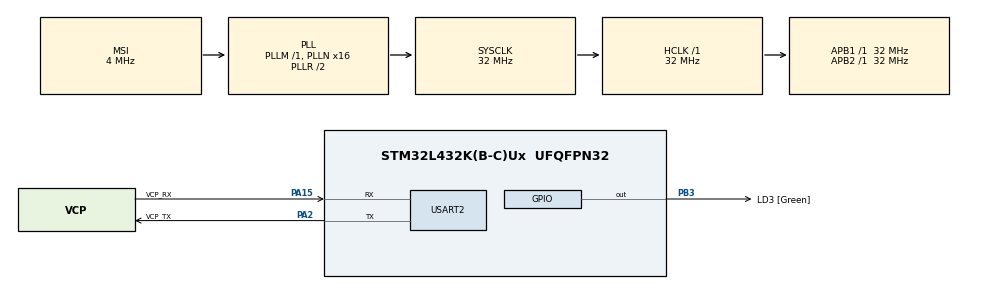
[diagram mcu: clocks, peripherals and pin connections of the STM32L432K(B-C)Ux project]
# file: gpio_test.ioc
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FREERTOS.BinarySemaphores01=myBinarySem01,Dynamic,NULL
FREERTOS.Mutexes01=myMutex01,Dynamic,NULL
FREERTOS.Tasks01=defaultTask,0,128,Task0,Default,NULL,Dynamic,NULL,NULL;myTask02,-3,128,Task1,Default,NULL,Dynamic,NULL,NULL;myTask03,-3,128,Task2,Default,NULL,Dynamic,NULL,NULL
Mcu.Family=STM32L4
Mcu.Name=STM32L432K(B-C)Ux
Mcu.Package=UFQFPN32
NVIC.PriorityGroup=NVIC_PRIORITYGROUP_4
PA0.GPIO_Label=MCO [High speed clock in]
PA0.Mode=HSE-External-Clock-Source-for-LittleOrca
PA0.Signal=RCC_CK_IN
PA13\ (JTMS-SWDIO).GPIO_Label=SWDIO
PA13\ (JTMS-SWDIO).Mode=Serial_Wire
PA13\ (JTMS-SWDIO).Signal=SYS_JTMS-SWDIO
PA14\ (JTCK-SWCLK).GPIO_Label=SWCLK
PA14\ (JTCK-SWCLK).Mode=Serial_Wire
PA14\ (JTCK-SWCLK).Signal=SYS_JTCK-SWCLK
PA15\ (JTDI).GPIO_Label=VCP_RX
PA15\ (JTDI).Mode=Asynchronous
PA15\ (JTDI).Signal=USART2_RX
PA2.GPIO_Label=VCP_TX
PA2.Mode=Asynchronous
PA2.Signal=USART2_TX
PB3\ (JTDO-TRACESWO).GPIO_Label=LD3 [Green]
PB3\ (JTDO-TRACESWO).Signal=GPIO_Output
PC14-OSC32_IN\ (PC14).Mode=LSE-External-Oscillator
PC14-OSC32_IN\ (PC14).Signal=RCC_OSC32_IN
PC15-OSC32_OUT\ (PC15).Mode=LSE-External-Oscillator
PC15-OSC32_OUT\ (PC15).Signal=RCC_OSC32_OUT
ProjectManager.HeapSize=0x200
ProjectManager.StackSize=0x400
ProjectManager.TargetToolchain=Makefile
RCC.AHBFreq_Value=32000000
RCC.APB1Freq_Value=32000000
RCC.APB1TimFreq_Value=32000000
RCC.APB2Freq_Value=32000000
RCC.APB2TimFreq_Value=32000000
RCC.CortexFreq_Value=32000000
RCC.HCLKFreq_Value=32000000
RCC.HSE_VALUE=8000000
RCC.HSI16_VALUE=16000000
RCC.HSI48_VALUE=48000000
RCC.HSI_VALUE=16000000
RCC.MSI_VALUE=4000000
RCC.PLLMUL=RCC_PLLMUL_4
RCC.PLLN=16
RCC.SYSCLKFreq_VALUE=32000000
RCC.SYSCLKSource=RCC_SYSCLKSOURCE_PLLCLK
RCC.VCOOutputFreq_Value=64000000
USART2.VirtualMode-Asynchronous=VM_ASYNC
VP_FREERTOS_VS_CMSIS_V1.Mode=CMSIS_V1
board=NUCLEO-L432KC

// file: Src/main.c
/* USER CODE BEGIN Header */
/**
  ******************************************************************************
  * @file           : main.c
  * @brief          : Main program body
  ******************************************************************************
  * @attention
  *
  * <h2><center>&copy; Copyright (c) 2019 STMicroelectronics.
  * All rights reserved.</center></h2>
  *
  * This software component is licensed by ST under Ultimate Liberty license
  * SLA0044, the "License"; You may not use this file except in compliance with
  * the License. You may obtain a copy of the License at:
  *                             www.st.com/SLA0044
  *
  ******************************************************************************
  */
/* USER CODE END Header */

#include "main.h"
#include "cmsis_os.h"
#include "usart.h"
#include "gpio.h"

void SystemClock_Config(void);
void MX_FREERTOS_Init(void);

int main(void) {

    /* MCU Configuration--------------------------------------------------------*/

    /* Reset of all peripherals, Initializes the Flash interface and the Systick. */
    HAL_Init();

    /* Configure the system clock */
    SystemClock_Config();

    /* Initialize all configured peripherals */
    MX_GPIO_Init();
    MX_USART2_UART_Init();

    /* Call init function for freertos objects (in freertos.c) */
    MX_FREERTOS_Init();

    /* Start scheduler */
    osKernelStart();

    /* We should never get here as control is now taken by the scheduler */

    /* Infinite loop */
    while (1) {

    }
}

void SystemClock_Config(void) {
    RCC_OscInitTypeDef RCC_OscInitStruct = {0};
    RCC_ClkInitTypeDef RCC_ClkInitStruct = {0};
    RCC_PeriphCLKInitTypeDef PeriphClkInit = {0};

    /** Configure LSE Drive Capability
    */
    HAL_PWR_EnableBkUpAccess();
    __HAL_RCC_LSEDRIVE_CONFIG(RCC_LSEDRIVE_LOW);
    /** Initializes the CPU, AHB and APB busses clocks
    */
    RCC_OscInitStruct.OscillatorType = RCC_OSCILLATORTYPE_LSE|RCC_OSCILLATORTYPE_MSI;
    RCC_OscInitStruct.LSEState = RCC_LSE_ON;
    RCC_OscInitStruct.MSIState = RCC_MSI_ON;
    RCC_OscInitStruct.MSICalibrationValue = 0;
    RCC_OscInitStruct.MSIClockRange = RCC_MSIRANGE_6;
    RCC_OscInitStruct.PLL.PLLState = RCC_PLL_ON;
    RCC_OscInitStruct.PLL.PLLSource = RCC_PLLSOURCE_MSI;
    RCC_OscInitStruct.PLL.PLLM = 1;
    RCC_OscInitStruct.PLL.PLLN = 16;
    RCC_OscInitStruct.PLL.PLLP = RCC_PLLP_DIV7;
    RCC_OscInitStruct.PLL.PLLQ = RCC_PLLQ_DIV2;
    RCC_OscInitStruct.PLL.PLLR = RCC_PLLR_DIV2;
    if (HAL_RCC_OscConfig(&RCC_OscInitStruct) != HAL_OK) {
        Error_Handler();
    }
    /** Initializes the CPU, AHB and APB busses clocks
    */
    RCC_ClkInitStruct.ClockType = RCC_CLOCKTYPE_HCLK|RCC_CLOCKTYPE_SYSCLK
                                  |RCC_CLOCKTYPE_PCLK1|RCC_CLOCKTYPE_PCLK2;
    RCC_ClkInitStruct.SYSCLKSource = RCC_SYSCLKSOURCE_PLLCLK;
    RCC_ClkInitStruct.AHBCLKDivider = RCC_SYSCLK_DIV1;
    RCC_ClkInitStruct.APB1CLKDivider = RCC_HCLK_DIV1;
    RCC_ClkInitStruct.APB2CLKDivider = RCC_HCLK_DIV1;

    if (HAL_RCC_ClockConfig(&RCC_ClkInitStruct, FLASH_LATENCY_1) != HAL_OK) {
        Error_Handler();
    }
    PeriphClkInit.PeriphClockSelection = RCC_PERIPHCLK_USART2;
    PeriphClkInit.Usart2ClockSelection = RCC_USART2CLKSOURCE_PCLK1;
    if (HAL_RCCEx_PeriphCLKConfig(&PeriphClkInit) != HAL_OK) {
        Error_Handler();
    }
    /** Configure the main internal regulator output voltage
    */
    if (HAL_PWREx_ControlVoltageScaling(PWR_REGULATOR_VOLTAGE_SCALE1) != HAL_OK) {
        Error_Handler();
    }
    /** Enable MSI Auto calibration
    */
    HAL_RCCEx_EnableMSIPLLMode();
}

void Error_Handler(void) {
}

/************************ (C) COPYRIGHT STMicroelectronics *****END OF FILE****/

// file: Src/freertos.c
/* USER CODE BEGIN Header */
/**
  ******************************************************************************
  * File Name          : freertos.c
  * Description        : Code for freertos applications
  ******************************************************************************
  * @attention
  *
  * <h2><center>&copy; Copyright (c) 2019 STMicroelectronics.
  * All rights reserved.</center></h2>
  *
  * This software component is licensed by ST under Ultimate Liberty license
  * SLA0044, the "License"; You may not use this file except in compliance with
  * the License. You may obtain a copy of the License at:
  *                             www.st.com/SLA0044
  *
  ******************************************************************************
  */
/* USER CODE END Header */

#include "FreeRTOS.h"
#include "task.h"
#include "main.h"
#include "cmsis_os.h"

/* USER CODE BEGIN Includes */
#include "gpio.h"
#include "usart.h"
#include <stdio.h>
#include <string.h>
/* USER CODE END Includes */

osThreadId defaultTaskHandle;
osThreadId myTask02Handle;
osThreadId myTask03Handle;
osMutexId myMutex01Handle;
osSemaphoreId myBinarySem01Handle;

void Task0(void const * argument);
void Task1(void const * argument);
void Task2(void const * argument);

void MX_FREERTOS_Init(void); /* (MISRA C 2004 rule 8.1) */

void MX_FREERTOS_Init(void) {

    /* Create the mutex(es) */
    /* definition and creation of myMutex01 */
    osMutexDef(myMutex01);
    myMutex01Handle = osMutexCreate(osMutex(myMutex01));

    /* Create the semaphores(s) */
    /* definition and creation of myBinarySem01 */
    osSemaphoreDef(myBinarySem01);
    myBinarySem01Handle = osSemaphoreCreate(osSemaphore(myBinarySem01), 1);

    /* Create the thread(s) */
    /* definition and creation of defaultTask */
    osThreadDef(defaultTask, Task0, osPriorityNormal, 0, 128);
    defaultTaskHandle = osThreadCreate(osThread(defaultTask), NULL);

    /* definition and creation of myTask02 */
    osThreadDef(myTask02, Task1, osPriorityIdle, 0, 128);
    myTask02Handle = osThreadCreate(osThread(myTask02), NULL);

    /* definition and creation of myTask03 */
    osThreadDef(myTask03, Task2, osPriorityIdle, 0, 128);
    myTask03Handle = osThreadCreate(osThread(myTask03), NULL);

}

void Task0(void const * argument) {

    for(;;) {
        osDelay(1);
    }
}

void Task1(void const * argument) {
    /* USER CODE BEGIN Task1 */

    GPIO_InitTypeDef GPIO_InitStruct = {0};

    /*Configure GPIO pin Output Level */
    HAL_GPIO_WritePin(GPIOA, GPIO_PIN_4, GPIO_PIN_RESET);
    HAL_GPIO_WritePin(GPIOA, GPIO_PIN_5, GPIO_PIN_SET);

    /*Configure GPIO pin : PA_4 */
    GPIO_InitStruct.Pin = GPIO_PIN_4;
    GPIO_InitStruct.Mode = GPIO_MODE_OUTPUT_PP;
    GPIO_InitStruct.Pull = GPIO_NOPULL;
    GPIO_InitStruct.Speed = GPIO_SPEED_FREQ_LOW;
    HAL_GPIO_Init(GPIOA, &GPIO_InitStruct);

    /*Configure GPIO pin : PA_5 */
    GPIO_InitStruct.Pin = GPIO_PIN_5;
    GPIO_InitStruct.Mode = GPIO_MODE_OUTPUT_PP;
    GPIO_InitStruct.Pull = GPIO_NOPULL;
    GPIO_InitStruct.Speed = GPIO_SPEED_FREQ_LOW;
    HAL_GPIO_Init(GPIOA, &GPIO_InitStruct);

    for(;;) {
        HAL_GPIO_TogglePin(GPIOB, GPIO_PIN_3);  // LED
        HAL_GPIO_TogglePin(GPIOA, GPIO_PIN_4);  // A3
        HAL_GPIO_TogglePin(GPIOA, GPIO_PIN_5);  // A4
        HAL_Delay(100);
        osDelay(100);
    }
    /* USER CODE END Task1 */
}

void Task2(void const * argument) {
    /* USER CODE BEGIN Task2 */
    /* Infinite loop */
    char buffer[16] = {0};
    int cnt = 0;
    for(;;) {
        cnt += 1;
        snprintf(&buffer[0], sizeof(buffer), "%i\n", cnt);
        HAL_UART_Transmit(&huart2, (uint8_t *)&buffer[0], strlen(buffer), 10);
        osDelay(100);
        HAL_Delay(100);
    }
    /* USER CODE END Task2 */
}

/************************ (C) COPYRIGHT STMicroelectronics *****END OF FILE****/
